# EFM32JG1B200F256GM48 register map
File version: 4.2.0
Registers are 32-bit, read-write, reset 0x0 unless marked. A register's access mark holds for its fields unless they carry their own. Offsets are from the block's base; [hi:lo] are bit positions; {n}, {i} and the like mark numbered series.

## CRYPTO
Base 0x400F0000
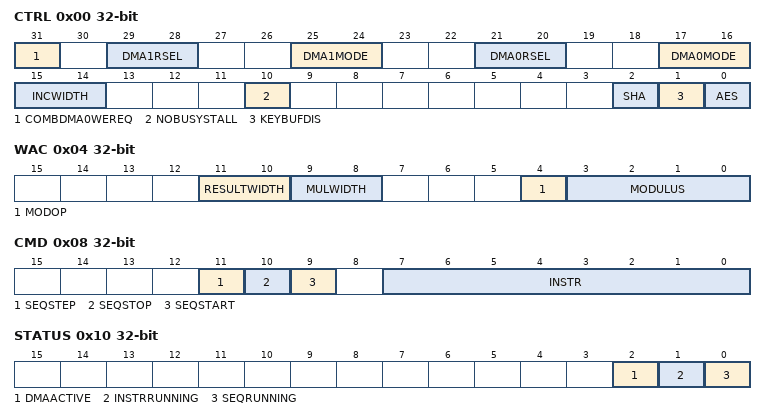
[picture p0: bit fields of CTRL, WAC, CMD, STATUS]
0x00 CTRL — Control Register
  [31] COMBDMA0WEREQ — Combined Data0 Write DMA Request
  [29:28] DMA1RSEL — DATA0 DMA Unaligned Read Register Select
    0=DATA1; 1=DDATA1; 2=QDATA1; 3=QDATA1BIG
  [25:24] DMA1MODE — DMA1 Read Mode
    0=FULL (Target register is fully read/written during every DMA transaction); 1=LENLIMIT (Length Limited. When the current length, i.e. LENGTHA or LENGTHB indicates that there are less bytes available than the register size, only length + 1 bytes + necessary zero padding is read. Zero padding is automatically added when writing.); 2=FULLBYTE (Target register is fully read/written during every DMA transaction. Bytewise DMA.); 3=LENLIMITBYTE (Length Limited. When the current length, i.e. LENGTHA or LENGTHB indicates that there are less bytes available than the register size, only length + 1 bytes + necessary zero padding is read. Bytewise DMA. Zero padding is automatically added when writing.)
  [21:20] DMA0RSEL — DMA0 Read Register Select
    0=DATA0; 1=DDATA0; 2=DDATA0BIG; 3=QDATA0
  [17:16] DMA0MODE — DMA0 Read Mode
    0=FULL (Target register is fully read/written during every DMA transaction); 1=LENLIMIT (Length Limited. When the current length, i.e. LENGTHA or LENGTHB indicates that there are less bytes available than the register size, only length + necessary zero padding is read. Zero padding is automatically added when writing.); 2=FULLBYTE (Target register is fully read/written during every DMA transaction. Bytewise DMA.); 3=LENLIMITBYTE (Length Limited. When the current length, i.e. LENGTHA or LENGTHB indicates that there are less bytes available than the register size, only length + necessary zero padding is read. Bytewise DMA. Zero padding is automatically added when writing.)
  [15:14] INCWIDTH — Increment Width
    0=Byte 15 in DATA1 is used for the increment function; 1=Bytes 14 and 15 in DATA1 are used for the increment function; 2=Bytes 13 to 15 in DATA1 are used for the increment function; 3=Bytes 12 to 15 in DATA1 are used for the increment function
  [10] NOBUSYSTALL — No Stalling of Bus When Busy
  [2] SHA — SHA Mode
  [1] KEYBUFDIS — Key Buffer Disable
  [0] AES — AES Mode
0x04 WAC — Wide Arithmetic Configuration
  [11:10] RESULTWIDTH
    0=256BIT (Results have 256 bits); 1=128BIT (Results have 128 bits); 2=260BIT (Results have 260 bits. Upper bits of result can be read through DDATA0MSBS in CRYPTO_STATUS)
  [9:8] MULWIDTH — Multiply Width
    0=MUL256 (Multiply 256 bits); 1=MUL128 (Multiply 128 bits); 2=MULMOD (Same number of bits as specified by MODULUS)
  [4] MODOP — Modular Operation Field Type
  [3:0] MODULUS — Modular Operation Modulus
    0=BIN256 (Generic modulus. p = 2^256); 1=BIN128 (Generic modulus. p = 2^128); 2=ECCBIN233P (Modulus for B-233 and K-233 ECC curves. p(t) = t^233 + t^74 + 1); 3=ECCBIN163P (Modulus for B-163 and K-163 ECC curves. p(t) = t^163 + t^7 + t^6 + t^3 + 1); 4=GCMBIN128 (Modulus for GCM. P(t) = t^128 + t^7 + t^2 + t + 1); 5=ECCPRIME256P (Modulus for P-256 ECC curve. p = 2^256 - 2^224 + 2^192 + 2^96 - 1); 6=ECCPRIME224P (Modulus for P-224 ECC curve. p = 2^224 - 2^96 - 1); 7=ECCPRIME192P (Modulus for P-192 ECC curve. p = 2^192 - 2^64 - 1); 8=ECCBIN233N (P modulus for B-233 ECC curve); 9=ECCBIN233KN (P modulus for K-233 ECC curve); 10=ECCBIN163N (P modulus for B-163 ECC curve); 11=ECCBIN163KN (P modulus for K-163 ECC curve); 12=ECCPRIME256N (P modulus for P-256 ECC curve); 13=ECCPRIME224N (P modulus for P-224 ECC curve); 14=ECCPRIME192N (P modulus for P-192 ECC curve)
0x08 CMD — Command Register
  [11] SEQSTEP wo — Sequence Step
  [10] SEQSTOP wo — Sequence Stop
  [9] SEQSTART wo — Encryption/Decryption SEQUENCE Start
  [7:0] INSTR — Execute Instruction
0x10 STATUS ro
  [2] DMAACTIVE — DMA Action is active
  [1] INSTRRUNNING — Action is active
  [0] SEQRUNNING — AES SEQUENCE Running
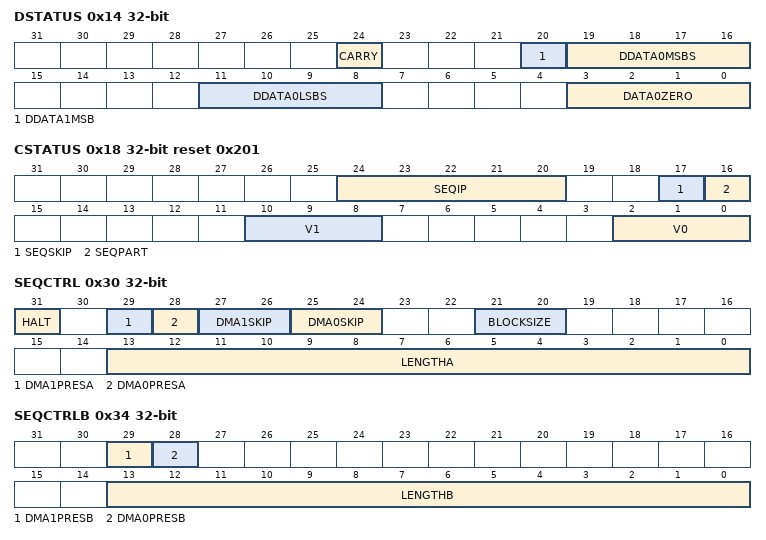
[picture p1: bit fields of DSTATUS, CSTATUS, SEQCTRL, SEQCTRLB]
0x14 DSTATUS ro — Data Status Register
  [24] CARRY — Carry From Arithmetic Operation
  [20] DDATA1MSB — MSB in DDATA1
  [19:16] DDATA0MSBS — MSB in DDATA0
  [11:8] DDATA0LSBS — LSBs in DDATA0
  [3:0] DATA0ZERO
    1=ZERO0TO31 (In DATA0 bits 0 to 31 are all zero.); 2=ZERO32TO63 (In DATA0 bits 32 to 63 are all zero.); 4=ZERO64TO95 (In DATA0 bits 64 to 95 are all zero.); 8=ZERO96TO127 (In DATA0 bits 96 to 127 are all zero.)
0x18 CSTATUS ro reset 0x201 — Control Status Register
  [24:20] SEQIP — Sequence Next Instruction Pointer
  [17] SEQSKIP — Sequence Skip Next Instruction
  [16] SEQPART — Sequence Part
  [10:8] V1 — Selected ALU Operand 1
    {v}=DDATA{v} (v=0..4); 5=DATA0; 6=DATA1; 7=DATA2
  [2:0] V0 — Selected ALU Operand 0
    {v}=DDATA{v} (v=0..4); 5=DATA0; 6=DATA1; 7=DATA2
0x20 KEY read-has-side-effects — KEY Register Access
  [31:0] KEY — Key Access
0x24 KEYBUF read-has-side-effects — KEY Buffer Register Access
  [31:0] KEYBUF — Key Buffer Access
0x30 SEQCTRL — Sequence Control
  [31] HALT — Halt Sequence
  [29] DMA1PRESA — DMA1 Preserve A
  [28] DMA0PRESA — DMA0 Preserve A
  [27:26] DMA1SKIP
  [25:24] DMA0SKIP
  [21:20] BLOCKSIZE — Size of data blocks
    0=16BYTES (A block is 16 bytes long); 1=32BYTES (A block is 32 bytes long); 2=64BYTES (A block is 64 bytes long)
  [13:0] LENGTHA — Buffer length A in bytes
0x34 SEQCTRLB — Sequence Control B
  [29] DMA1PRESB — DMA1 Preserve B
  [28] DMA0PRESB — DMA0 Preserve B
  [13:0] LENGTHB — Buffer length B in bytes
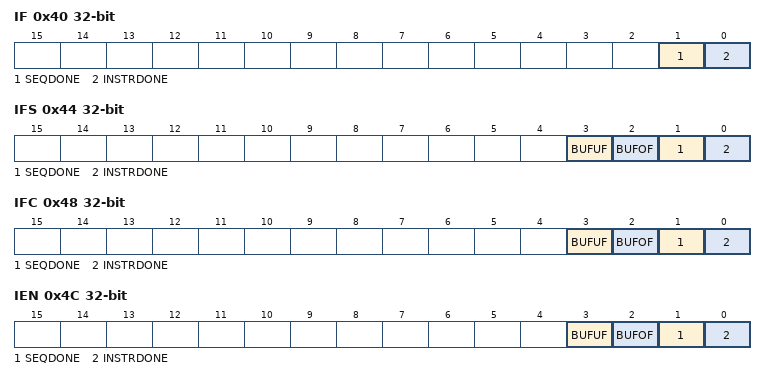
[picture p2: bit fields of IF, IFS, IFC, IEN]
0x40 IF ro — AES Interrupt Flags
  [1] SEQDONE — Sequence Done
  [0] INSTRDONE — Instruction done
0x44 IFS wo — Interrupt Flag Set Register
  [3] BUFUF — Set BUFUF Interrupt Flag
  [2] BUFOF — Set BUFOF Interrupt Flag
  [1] SEQDONE — Set SEQDONE Interrupt Flag
  [0] INSTRDONE — Set INSTRDONE Interrupt Flag
0x48 IFC wo — Interrupt Flag Clear Register
  [3] BUFUF — Clear BUFUF Interrupt Flag
  [2] BUFOF — Clear BUFOF Interrupt Flag
  [1] SEQDONE — Clear SEQDONE Interrupt Flag
  [0] INSTRDONE — Clear INSTRDONE Interrupt Flag
0x4C IEN — Interrupt Enable Register
  [3] BUFUF — BUFUF Interrupt Enable
  [2] BUFOF — BUFOF Interrupt Enable
  [1] SEQDONE — SEQDONE Interrupt Enable
  [0] INSTRDONE — INSTRDONE Interrupt Enable
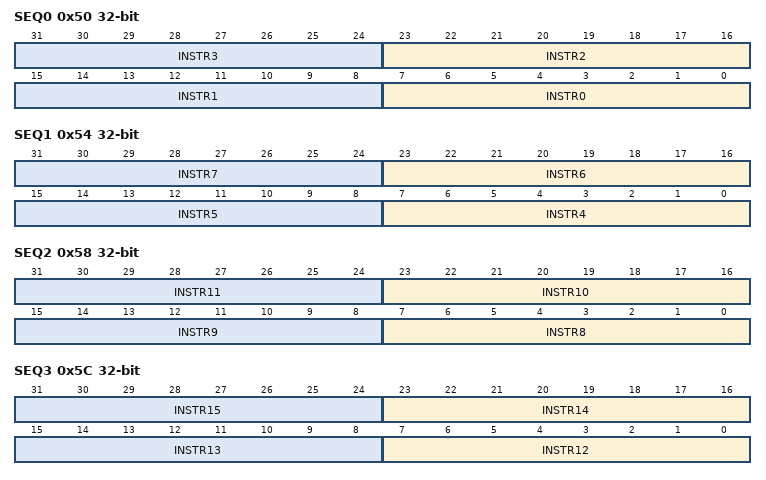
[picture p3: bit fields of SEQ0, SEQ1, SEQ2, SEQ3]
0x50 SEQ0 — Sequence register 0
  [8n+7:8n] INSTR{n} (n=0..3) — Sequence Instruction {n}
0x54 SEQ1 — Sequence Register 1
  [8n-25:8n-32] INSTR{n} (n=4..7) — Sequence Instruction {n}
0x58 SEQ2 — Sequence Register 2
  [8n-57:8n-64] INSTR{n} (n=8..11) — Sequence Instruction {n}
0x5C SEQ3 — Sequence Register 3
  [8n-89:8n-96] INSTR{n} (n=12..15) — Sequence Instruction {n}
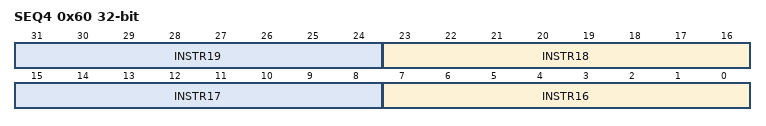
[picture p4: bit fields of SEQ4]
0x60 SEQ4 — Sequence Register 4
  [8n-121:8n-128] INSTR{n} (n=16..19) — Sequence Instruction {n}
{0x80+4i} DATA{i} read-has-side-effects (i=0..3) — DATA{i} Register Access
  [31:0] DATA{i} — Data {i} Access
0xA0 DATA0XOR read-has-side-effects — DATA0XOR Register Access
  [31:0] DATA0XOR — XOR Data 0 Access
0xB0 DATA0BYTE read-has-side-effects — DATA0 Register Byte Access
  [7:0] DATA0BYTE — Data 0 Byte Access
0xB4 DATA1BYTE read-has-side-effects — DATA1 Register Byte Access
  [7:0] DATA1BYTE — Data 1 Byte Access
0xBC DATA0XORBYTE read-has-side-effects — DATA0 Register Byte XOR Access
  [7:0] DATA0XORBYTE — Data 0 XOR Byte Access
{0x90+4i} DATA0BYTE{i} (i=12..15) — DATA0 Register Byte {i} Access
  [7:0] DATA0BYTE{i} — Data 0 Byte {i} Access
{0x100+4i} DDATA{i} read-has-side-effects (i=0..4) — DDATA{i} Register Access
  [31:0] DDATA{i} — Double Data 0 Access
0x130 DDATA0BIG read-has-side-effects — DDATA0 Register Big Endian Access
  [31:0] DDATA0BIG — Double Data 0 Big Endian Access
0x140 DDATA0BYTE read-has-side-effects — DDATA0 Register Byte Access
  [7:0] DDATA0BYTE — Ddata 0 Byte Access
0x144 DDATA1BYTE read-has-side-effects — DDATA1 Register Byte Access
  [7:0] DDATA1BYTE — Ddata 1 Byte Access
0x148 DDATA0BYTE32 — DDATA0 Register Byte 32 access.
  [3:0] DDATA0BYTE32 — Ddata 0 Byte 32 Access
0x180 QDATA0 read-has-side-effects — QDATA0 Register Access
  [31:0] QDATA0 — Quad Data 0 Access
0x184 QDATA1 read-has-side-effects — QDATA1 Register Access
  [31:0] QDATA1 — Quad Data 1 Access
0x1A4 QDATA1BIG read-has-side-effects — QDATA1 Register Big Endian Access
  [31:0] QDATA1BIG — Quad Data 1 Big Endian Access
0x1C0 QDATA0BYTE read-has-side-effects — QDATA0 Register Byte Access
  [7:0] QDATA0BYTE — Qdata 0 Byte Access
0x1C4 QDATA1BYTE read-has-side-effects — QDATA1 Register Byte Access
  [7:0] QDATA1BYTE — Qdata 1 Byte Access
